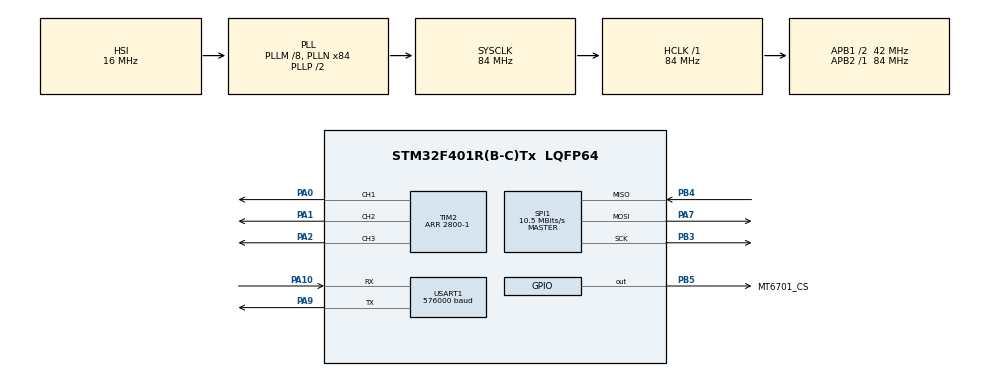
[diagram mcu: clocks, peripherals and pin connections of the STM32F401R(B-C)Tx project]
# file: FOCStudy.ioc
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Dma.Request0=USART1_TX
Dma.USART1_TX.0.Direction=DMA_MEMORY_TO_PERIPH
Dma.USART1_TX.0.FIFOMode=DMA_FIFOMODE_DISABLE
Dma.USART1_TX.0.Instance=DMA2_Stream7
Dma.USART1_TX.0.MemDataAlignment=DMA_MDATAALIGN_BYTE
Dma.USART1_TX.0.MemInc=DMA_MINC_ENABLE
Dma.USART1_TX.0.Mode=DMA_NORMAL
Dma.USART1_TX.0.PeriphDataAlignment=DMA_PDATAALIGN_BYTE
Dma.USART1_TX.0.PeriphInc=DMA_PINC_DISABLE
Dma.USART1_TX.0.Priority=DMA_PRIORITY_LOW
Mcu.Family=STM32F4
Mcu.Name=STM32F401R(B-C)Tx
Mcu.Package=LQFP64
NVIC.DMA2_Stream7_IRQn=true\:1\:0\:true\:false\:true\:false\:true\:true
NVIC.PriorityGroup=NVIC_PRIORITYGROUP_4
NVIC.TIM3_IRQn=true\:0\:0\:false\:false\:true\:true\:true\:true
NVIC.USART1_IRQn=true\:1\:0\:true\:false\:true\:true\:true\:true
PA0-WKUP.Signal=S_TIM2_CH1_ETR
PA1.Signal=S_TIM2_CH2
PA10.Mode=Asynchronous
PA10.Signal=USART1_RX
PA13.Mode=Serial_Wire
PA13.Signal=SYS_JTMS-SWDIO
PA14.Mode=Serial_Wire
PA14.Signal=SYS_JTCK-SWCLK
PA2.Signal=S_TIM2_CH3
PA7.Mode=Full_Duplex_Master
PA7.Signal=SPI1_MOSI
PA9.Mode=Asynchronous
PA9.Signal=USART1_TX
PB3.Mode=Full_Duplex_Master
PB3.Signal=SPI1_SCK
PB4.Mode=Full_Duplex_Master
PB4.Signal=SPI1_MISO
PB5.GPIO_Label=MT6701_CS
PB5.GPIO_Speed=GPIO_SPEED_FREQ_HIGH
PB5.PinState=GPIO_PIN_SET
PB5.Signal=GPIO_Output
PH0\ -\ OSC_IN.Mode=HSE-External-Oscillator
PH0\ -\ OSC_IN.Signal=RCC_OSC_IN
PH1\ -\ OSC_OUT.Mode=HSE-External-Oscillator
PH1\ -\ OSC_OUT.Signal=RCC_OSC_OUT
ProjectManager.HeapSize=0x200
ProjectManager.StackSize=0x400
ProjectManager.TargetToolchain=MDK-ARM V5.32
RCC.48MHZClocksFreq_Value=42000000
RCC.AHBFreq_Value=84000000
RCC.APB1CLKDivider=RCC_HCLK_DIV2
RCC.APB1Freq_Value=42000000
RCC.APB1TimFreq_Value=84000000
RCC.APB2Freq_Value=84000000
RCC.APB2TimFreq_Value=84000000
RCC.CortexFreq_Value=84000000
RCC.HCLKFreq_Value=84000000
RCC.HSE_VALUE=25000000
RCC.HSI_VALUE=16000000
RCC.LSE_VALUE=32768
RCC.PLLM=8
RCC.PLLN=84
RCC.SYSCLKFreq_VALUE=84000000
RCC.SYSCLKSource=RCC_SYSCLKSOURCE_PLLCLK
RCC.VCOOutputFreq_Value=168000000
SH.S_TIM2_CH1_ETR.0=TIM2_CH1,PWM Generation1 CH1
SH.S_TIM2_CH2.0=TIM2_CH2,PWM Generation2 CH2
SH.S_TIM2_CH3.0=TIM2_CH3,PWM Generation3 CH3
SPI1.BaudRatePrescaler=SPI_BAUDRATEPRESCALER_8
SPI1.CLKPhase=SPI_PHASE_2EDGE
SPI1.CLKPolarity=SPI_POLARITY_LOW
SPI1.CalculateBaudRate=10.5 MBits/s
SPI1.DataSize=SPI_DATASIZE_16BIT
SPI1.Direction=SPI_DIRECTION_2LINES
SPI1.Mode=SPI_MODE_MASTER
SPI1.VirtualType=VM_MASTER
TIM2.AutoReloadPreload=TIM_AUTORELOAD_PRELOAD_ENABLE
TIM2.Channel-PWM\ Generation1\ CH1=TIM_CHANNEL_1
TIM2.Channel-PWM\ Generation2\ CH2=TIM_CHANNEL_2
TIM2.Channel-PWM\ Generation3\ CH3=TIM_CHANNEL_3
TIM2.CounterMode=TIM_COUNTERMODE_CENTERALIGNED1
TIM2.Period=2800-1
TIM3.Period=1000-1
TIM3.Prescaler=84-1
USART1.BaudRate=576000
USART1.VirtualMode=VM_ASYNC
VP_TIM2_VS_ClockSourceINT.Mode=Internal
VP_TIM3_VS_ClockSourceINT.Mode=Internal
board=custom

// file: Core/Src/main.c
/* USER CODE BEGIN Header */
/**
 ******************************************************************************
 * @file           : main.c
 * @brief          : Main program body
 ******************************************************************************
 * @attention
 *
 * Copyright (c) 2023 STMicroelectronics.
 * All rights reserved.
 *
 * This software is licensed under terms that can be found in the LICENSE file
 * in the root directory of this software component.
 * If no LICENSE file comes with this software, it is provided AS-IS.
 *
 ******************************************************************************
 */
/* USER CODE END Header */
#include "main.h"
#include "dma.h"
#include "spi.h"
#include "tim.h"
#include "usart.h"
#include "gpio.h"

/* USER CODE BEGIN Includes */
#include "Serial.h"
#include "FOC.h"
#include "arm_math.h"
#include "motor.h"
#include "MT6701.h"
/* USER CODE END Includes */

void SystemClock_Config(void);

int main(void)
{

  /* MCU Configuration--------------------------------------------------------*/

  /* Reset of all peripherals, Initializes the Flash interface and the Systick. */
  HAL_Init();

  /* Configure the system clock */
  SystemClock_Config();

  /* Initialize all configured peripherals */
  MX_GPIO_Init();
  MX_DMA_Init();
  MX_USART1_UART_Init();
  MX_SPI1_Init();
  MX_TIM2_Init();
  MX_TIM3_Init();
  /* USER CODE BEGIN 2 */

  FOC_log("*******  FOC Init!  *******\r\n");

  PWM_Init(); // Enable the PWM output channel of Timx
  HAL_Delay(20);

  Align_Sensor(); // Calibrate the initial electrical Angle

  velocity_PID_Config();
  HAL_Delay(50);

  HAL_TIM_Base_Start_IT(&htim3); // Enable TIM3 timer interrupt
  FOC_log("******  FOC Enter Loop!  *********\r\n");

  /* USER CODE END 2 */

  /* Infinite loop */
  /* USER CODE BEGIN WHILE */
  while (1)
  {
    // OpenVelocity1(5.0f);
    // OpenVelocity2(0.5f);
    close_Velocity_LOG();
    // MT6701_log();
    /* USER CODE END WHILE */

  }
}

void SystemClock_Config(void)
{
  RCC_OscInitTypeDef RCC_OscInitStruct = {0};
  RCC_ClkInitTypeDef RCC_ClkInitStruct = {0};

  /** Configure the main internal regulator output voltage
   */
  __HAL_RCC_PWR_CLK_ENABLE();
  __HAL_PWR_VOLTAGESCALING_CONFIG(PWR_REGULATOR_VOLTAGE_SCALE2);

  /** Initializes the RCC Oscillators according to the specified parameters
   * in the RCC_OscInitTypeDef structure.
   */
  RCC_OscInitStruct.OscillatorType = RCC_OSCILLATORTYPE_HSI;
  RCC_OscInitStruct.HSIState = RCC_HSI_ON;
  RCC_OscInitStruct.HSICalibrationValue = RCC_HSICALIBRATION_DEFAULT;
  RCC_OscInitStruct.PLL.PLLState = RCC_PLL_ON;
  RCC_OscInitStruct.PLL.PLLSource = RCC_PLLSOURCE_HSI;
  RCC_OscInitStruct.PLL.PLLM = 8;
  RCC_OscInitStruct.PLL.PLLN = 84;
  RCC_OscInitStruct.PLL.PLLP = RCC_PLLP_DIV2;
  RCC_OscInitStruct.PLL.PLLQ = 4;
  if (HAL_RCC_OscConfig(&RCC_OscInitStruct) != HAL_OK)
  {
    Error_Handler();
  }

  /** Initializes the CPU, AHB and APB buses clocks
   */
  RCC_ClkInitStruct.ClockType = RCC_CLOCKTYPE_HCLK | RCC_CLOCKTYPE_SYSCLK | RCC_CLOCKTYPE_PCLK1 | RCC_CLOCKTYPE_PCLK2;
  RCC_ClkInitStruct.SYSCLKSource = RCC_SYSCLKSOURCE_PLLCLK;
  RCC_ClkInitStruct.AHBCLKDivider = RCC_SYSCLK_DIV1;
  RCC_ClkInitStruct.APB1CLKDivider = RCC_HCLK_DIV2;
  RCC_ClkInitStruct.APB2CLKDivider = RCC_HCLK_DIV1;

  if (HAL_RCC_ClockConfig(&RCC_ClkInitStruct, FLASH_LATENCY_2) != HAL_OK)
  {
    Error_Handler();
  }
}

void Error_Handler(void)
{
  __disable_irq();
  while (1)
  {
  }
}
